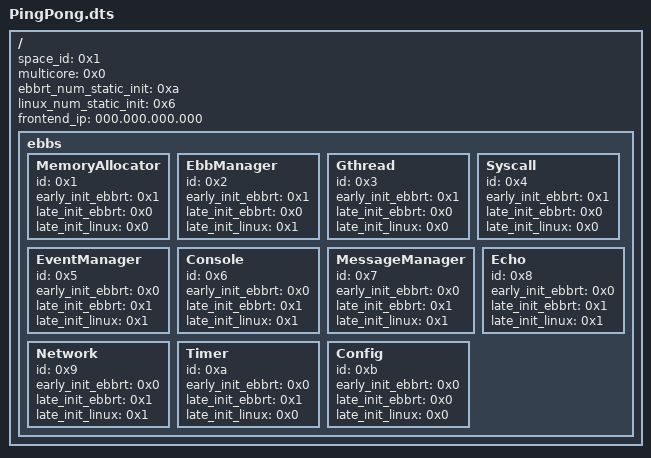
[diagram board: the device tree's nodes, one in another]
/dts-v1/;
/ {
  space_id = <0x1>;
  multicore = <0x0>;
  ebbrt_num_static_init = <0xa>;
  linux_num_static_init = <0x6>;
  frontend_ip = "000.000.000.000";
  ebbs
  {
    MemoryAllocator{
      id = <0x1>;
      early_init_ebbrt = <0x1>;
      late_init_ebbrt  = <0x0>;
      late_init_linux  = <0x0>;
    };
    EbbManager{
      id = <0x2>;
      early_init_ebbrt = <0x1>;
      late_init_ebbrt  = <0x0>;
      late_init_linux  = <0x1>;
    };
    Gthread{
      id = <0x3>;
      early_init_ebbrt = <0x1>;
      late_init_ebbrt  = <0x0>;
      late_init_linux  = <0x0>;
    };
    Syscall{
      id = <0x4>;
      early_init_ebbrt = <0x1>;
      late_init_ebbrt  = <0x0>;
      late_init_linux  = <0x0>;
    };
    EventManager{
      id = <0x5>;
      early_init_ebbrt = <0x0>;
      late_init_ebbrt  = <0x1>;
      late_init_linux  = <0x1>;
    };
    Console{
      id = <0x6>;
      early_init_ebbrt = <0x0>;
      late_init_ebbrt  = <0x1>;
      late_init_linux  = <0x1>;
    };
    MessageManager{
      id = <0x7>;
      early_init_ebbrt = <0x0>;
      late_init_ebbrt  = <0x1>;
      late_init_linux  = <0x1>;
    };
    Echo{
      id = <0x8>;
      early_init_ebbrt = <0x0>;
      late_init_ebbrt  = <0x1>;
      late_init_linux  = <0x1>;
    };
    Network{
      id = <0x9>;
      early_init_ebbrt = <0x0>;
      late_init_ebbrt  = <0x1>;
      late_init_linux  = <0x1>;
    };
    Timer{
      id = <0xa>;
      early_init_ebbrt = <0x0>;
      late_init_ebbrt  = <0x1>;
      late_init_linux  = <0x0>;
    };
    Config{
      id = <0xb>;
      early_init_ebbrt = <0x0>;
      late_init_ebbrt  = <0x0>;
      late_init_linux  = <0x0>;
    };
  };
};

